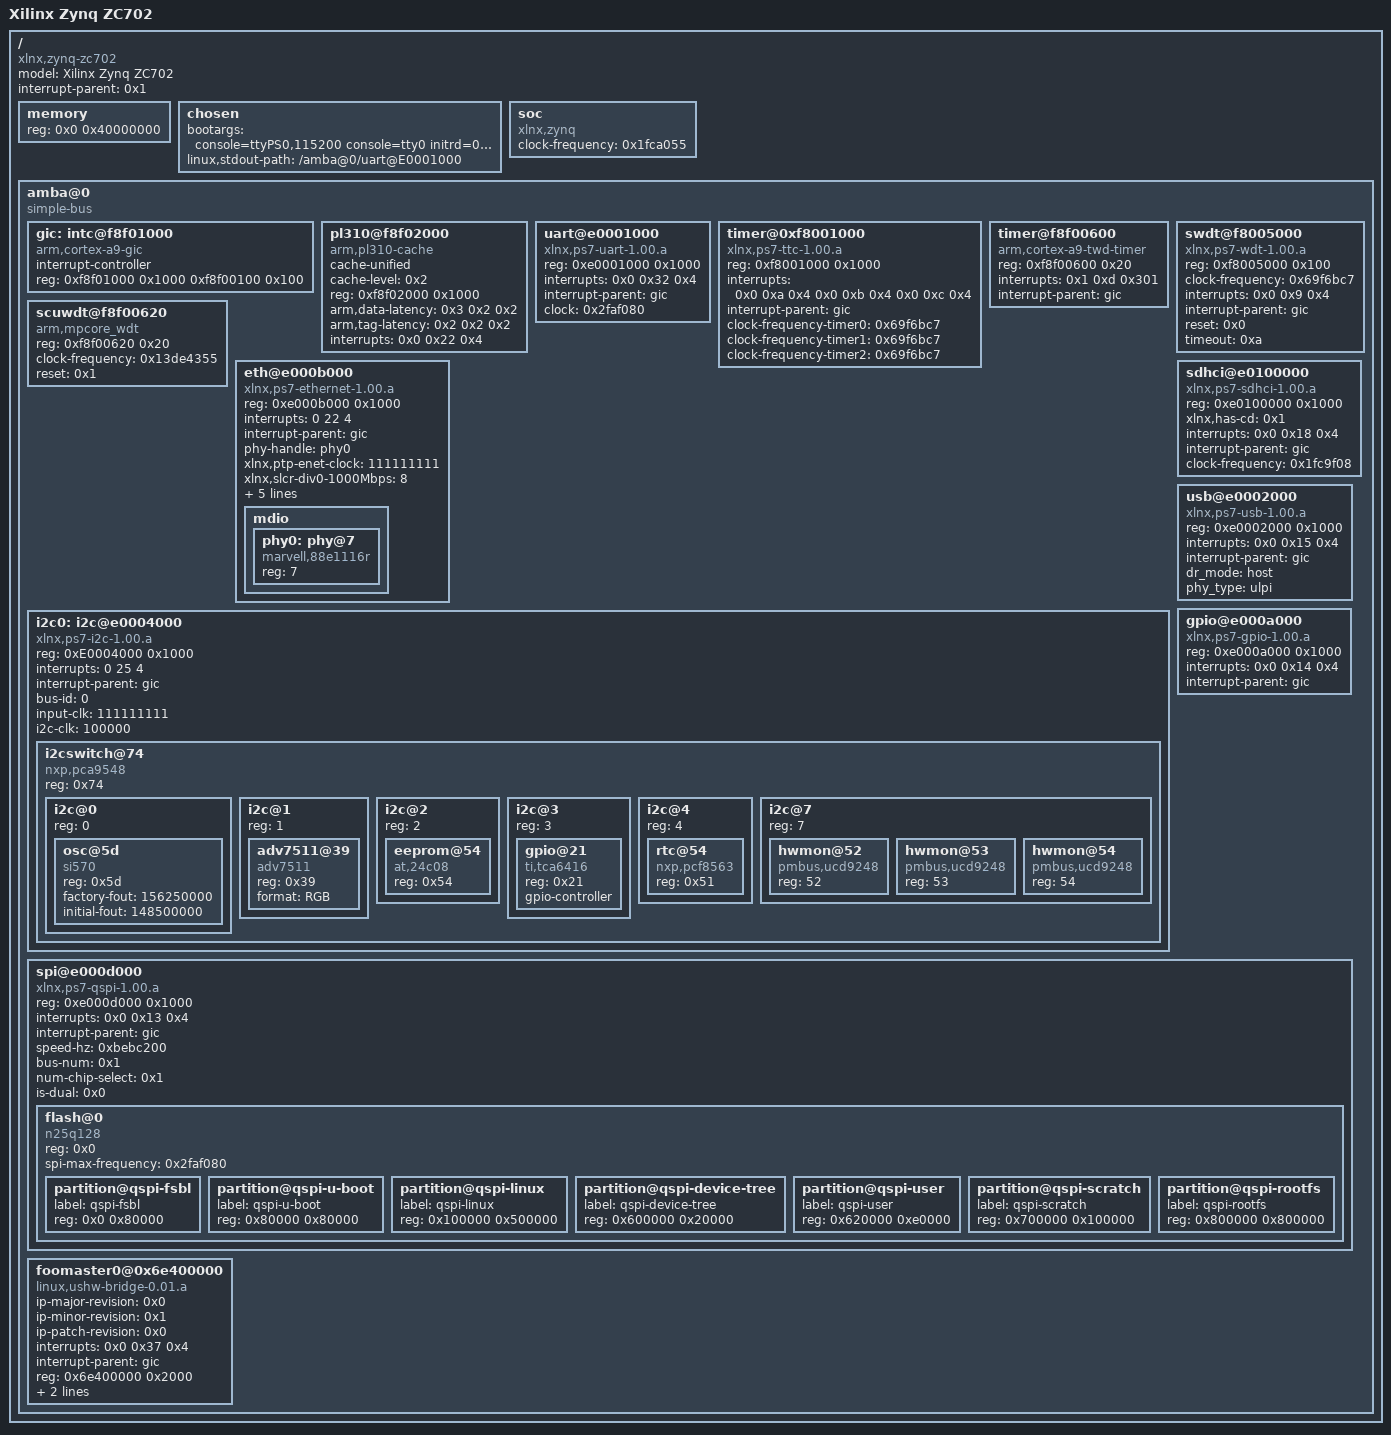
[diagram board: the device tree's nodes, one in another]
/dts-v1/;

/ {
	model = "Xilinx Zynq ZC702";
	compatible = "xlnx,zynq-zc702";
	#address-cells = <0x1>;
	#size-cells = <0x1>;
	interrupt-parent = <0x1>;

	memory {
		device_type = "memory";
		reg = <0x0 0x40000000>;
	};

	chosen {
		bootargs = "console=ttyPS0,115200 console=tty0 initrd=0x00800000,256K noinitrd init=/init root=/dev/ram rw ip=:::::eth0:dhcp";
		linux,stdout-path = "/amba@0/uart@E0001000";
	};

	soc {
		compatible = "xlnx,zynq";
		clock-frequency = <0x1fca055>;
	};

	amba@0 {
		compatible = "simple-bus";
		#address-cells = <0x1>;
		#size-cells = <0x1>;
		ranges;

		gic: intc@f8f01000 {
			interrupt-controller;
			compatible = "arm,cortex-a9-gic";
			#interrupt-cells = <0x3>;
			reg = <0xf8f01000 0x1000 0xf8f00100 0x100>;
			linux,phandle = <0x1>;
			phandle = <0x1>;
		};

		pl310@f8f02000 {
			compatible = "arm,pl310-cache";
			cache-unified;
			cache-level = <0x2>;
			reg = <0xf8f02000 0x1000>;
			arm,data-latency = <0x3 0x2 0x2>;
			arm,tag-latency = <0x2 0x2 0x2>;
			interrupts = <0x0 0x22 0x4>;
		};

		uart@e0001000 {
			compatible = "xlnx,ps7-uart-1.00.a";
			reg = <0xe0001000 0x1000>;
			interrupts = <0x0 0x32 0x4>;
			interrupt-parent = <&gic>;
			clock = <0x2faf080>;
		};

		timer@0xf8001000 {
			compatible = "xlnx,ps7-ttc-1.00.a";
			reg = <0xf8001000 0x1000>;
			interrupts = <0x0 0xa 0x4 0x0 0xb 0x4 0x0 0xc 0x4>;
			interrupt-parent = <&gic>;
			clock-frequency-timer0 = <0x69f6bc7>;
			clock-frequency-timer1 = <0x69f6bc7>;
			clock-frequency-timer2 = <0x69f6bc7>;
		};

		timer@f8f00600 {
			compatible = "arm,cortex-a9-twd-timer";
			reg = <0xf8f00600 0x20>;
			interrupts = <0x1 0xd 0x301>;
			interrupt-parent = <&gic>;
		};

		swdt@f8005000 {
			device_type = "watchdog";
			compatible = "xlnx,ps7-wdt-1.00.a";
			reg = <0xf8005000 0x100>;
			clock-frequency = <0x69f6bc7>;
			interrupts = <0x0 0x9 0x4>;
			interrupt-parent = <&gic>;
			reset = <0x0>;
			timeout = <0xa>;
		};

		scuwdt@f8f00620 {
			device_type = "watchdog";
			compatible = "arm,mpcore_wdt";
			reg = <0xf8f00620 0x20>;
			clock-frequency = <0x13de4355>;
			reset = <0x1>;
		};

		eth@e000b000 {
			compatible = "xlnx,ps7-ethernet-1.00.a";
			reg = <0xe000b000 0x1000>;
			interrupts = <0 22 4>;
			interrupt-parent = <&gic>;
			phy-handle = <&phy0>;
			xlnx,ptp-enet-clock = <111111111>;
			xlnx,slcr-div0-1000Mbps = <8>;
			xlnx,slcr-div0-100Mbps = <8>;
			xlnx,slcr-div0-10Mbps = <8>;
			xlnx,slcr-div1-1000Mbps = <1>;
			xlnx,slcr-div1-100Mbps = <5>;
			xlnx,slcr-div1-10Mbps = <50>;
			#address-cells = <0x1>;
			#size-cells = <0x0>;
			mdio {
				#address-cells = <1>;
				#size-cells = <0>;
				phy0: phy@7 {
					compatible = "marvell,88e1116r";
					device_type = "ethernet-phy";
					reg = <7>;
				};
			};
		};

		i2c0: i2c@e0004000 {
			compatible = "xlnx,ps7-i2c-1.00.a";
			reg = <0xE0004000 0x1000>;
			interrupts = <0 25 4>;
			interrupt-parent = <&gic>;
			bus-id = <0>;
			input-clk = <111111111>;
			i2c-clk = <100000>;

			#address-cells = <1>;
			#size-cells = <0>;
                        i2cswitch@74 {
                                compatible = "nxp,pca9548";
                                #address-cells = <1>;
                                #size-cells = <0>;
                                reg = <0x74>;

				i2c@0 {
                                        #address-cells = <1>;
                                        #size-cells = <0>;
                                        reg = <0>;
                                        osc@5d {
                                                compatible = "si570";
                                                reg = <0x5d>;
						factory-fout = <156250000>;
						initial-fout = <148500000>;
                                        };
				};

				i2c@1 {
                                        #address-cells = <1>;
                                        #size-cells = <0>;
                                        reg = <1>;
                                        adv7511@39 {
                                                compatible = "adv7511";
                                                reg = <0x39>;
                                                format = "RGB";
                                        };
                                };

				i2c@2 {
                                        #address-cells = <1>;
                                        #size-cells = <0>;
                                        reg = <2>;
                                        eeprom@54 {
                                                compatible = "at,24c08";
                                                reg = <0x54>;
                                        };
                                };

				i2c@3 {
                                        #address-cells = <1>;
                                        #size-cells = <0>;
                                        reg = <3>;
                                        gpio@21 {
                                                compatible = "ti,tca6416";
                                                reg = <0x21>;
						gpio-controller;
						#gpio-cells = <2>;
                                        };
				};

				i2c@4 {
                                        #address-cells = <1>;
                                        #size-cells = <0>;
                                        reg = <4>;
                                        rtc@54 {
                                                compatible = "nxp,pcf8563";
                                                reg = <0x51>;
                                        };
				};

				i2c@7 {
                                        #address-cells = <1>;
                                        #size-cells = <0>;
                                        reg = <7>;
                                        hwmon@52{
                                                compatible = "pmbus,ucd9248";
                                                reg = <52>;
                                        };
                                        hwmon@53{
                                                compatible = "pmbus,ucd9248";
                                                reg = <53>;
                                        };
                                        hwmon@54{
                                                compatible = "pmbus,ucd9248";
                                                reg = <54>;
					};
				};
			};
		};

		sdhci@e0100000 {
			compatible = "xlnx,ps7-sdhci-1.00.a";
			reg = <0xe0100000 0x1000>;
			xlnx,has-cd = <0x1>;
			interrupts = <0x0 0x18 0x4>;
			interrupt-parent = <&gic>;
			clock-frequency = <0x1fc9f08>;
		};

		usb@e0002000 {
			compatible = "xlnx,ps7-usb-1.00.a";
			reg = <0xe0002000 0x1000>;
			interrupts = <0x0 0x15 0x4>;
			interrupt-parent = <&gic>;
			dr_mode = "host";
			phy_type = "ulpi";
		};

		gpio@e000a000 {
			compatible = "xlnx,ps7-gpio-1.00.a";
			reg = <0xe000a000 0x1000>;
			interrupts = <0x0 0x14 0x4>;
			interrupt-parent = <&gic>;
		};

		spi@e000d000 {
			compatible = "xlnx,ps7-qspi-1.00.a";
			reg = <0xe000d000 0x1000>;
			interrupts = <0x0 0x13 0x4>;
			interrupt-parent = <&gic>;
			speed-hz = <0xbebc200>;
			bus-num = <0x1>;
			num-chip-select = <0x1>;
			#address-cells = <0x1>;
			#size-cells = <0x0>;
			is-dual = <0x0>;

			flash@0 {
				compatible = "n25q128";
				reg = <0x0>;
				spi-max-frequency = <0x2faf080>;
				#address-cells = <0x1>;
				#size-cells = <0x1>;

				partition@qspi-fsbl {
					label = "qspi-fsbl";
					reg = <0x0 0x80000>;
				};

				partition@qspi-u-boot {
					label = "qspi-u-boot";
					reg = <0x80000 0x80000>;
				};

				partition@qspi-linux {
					label = "qspi-linux";
					reg = <0x100000 0x500000>;
				};

				partition@qspi-device-tree {
					label = "qspi-device-tree";
					reg = <0x600000 0x20000>;
				};

				partition@qspi-user {
					label = "qspi-user";
					reg = <0x620000 0xe0000>;
				};

				partition@qspi-scratch {
					label = "qspi-scratch";
					reg = <0x700000 0x100000>;
				};

				partition@qspi-rootfs {
					label = "qspi-rootfs";
					reg = <0x800000 0x800000>;
				};
			};
		};

		foomaster0@0x6e400000 {
			compatible = "linux,ushw-bridge-0.01.a";
			ip-major-revision = <0x0>;
			ip-minor-revision = <0x1>;
			ip-patch-revision = <0x0>;
			interrupts = <0x0 0x37 0x4>;
			interrupt-parent = <&gic>;
			reg = <0x6e400000 0x2000>;
			device-name = "foomaster0";
			fifo = <0x1000 0x8 0x8>;
		};
	};
};
